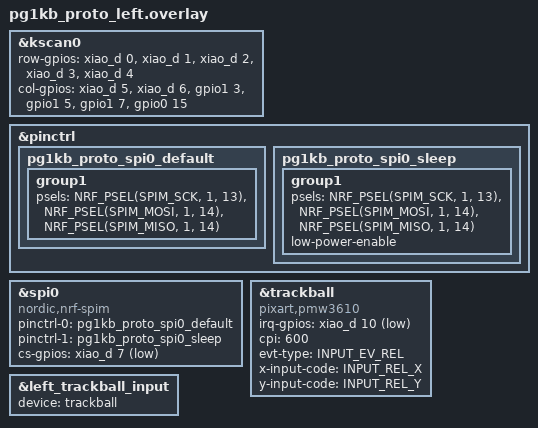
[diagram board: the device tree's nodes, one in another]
#include "pg1kb_proto.dtsi"

#include <zephyr/dt-bindings/input/input-event-codes.h>

&kscan0 {
    row-gpios
        = <&xiao_d 0 (GPIO_ACTIVE_HIGH | GPIO_PULL_DOWN)>
        , <&xiao_d 1 (GPIO_ACTIVE_HIGH | GPIO_PULL_DOWN)>
        , <&xiao_d 2 (GPIO_ACTIVE_HIGH | GPIO_PULL_DOWN)>
        , <&xiao_d 3 (GPIO_ACTIVE_HIGH | GPIO_PULL_DOWN)>
        , <&xiao_d 4 (GPIO_ACTIVE_HIGH | GPIO_PULL_DOWN)>
        ;

    col-gpios
        = <&xiao_d 5 GPIO_ACTIVE_HIGH>
        , <&xiao_d 6 GPIO_ACTIVE_HIGH>
        , <&gpio1 3 GPIO_ACTIVE_HIGH>
        , <&gpio1 5 GPIO_ACTIVE_HIGH>
        , <&gpio1 7 GPIO_ACTIVE_HIGH>
        , <&gpio0 15 GPIO_ACTIVE_HIGH>
        ;
};

&pinctrl {
    pg1kb_proto_spi0_default: pg1kb_proto_spi0_default {
        group1 {
            psels = <NRF_PSEL(SPIM_SCK, 1, 13)>,
                    <NRF_PSEL(SPIM_MOSI, 1, 14)>,
                    <NRF_PSEL(SPIM_MISO, 1, 14)>;
        };
    };

    pg1kb_proto_spi0_sleep: pg1kb_proto_spi0_sleep {
        group1 {
            psels = <NRF_PSEL(SPIM_SCK, 1, 13)>,
                    <NRF_PSEL(SPIM_MOSI, 1, 14)>,
                    <NRF_PSEL(SPIM_MISO, 1, 14)>;
            low-power-enable;
        };
    };
};

&spi0 {
    status = "okay";
    compatible = "nordic,nrf-spim";
    pinctrl-0 = <&pg1kb_proto_spi0_default>;
    pinctrl-1 = <&pg1kb_proto_spi0_sleep>;
    pinctrl-names = "default", "sleep";
    cs-gpios = <&xiao_d 7 GPIO_ACTIVE_LOW>;
};

&trackball {
    status = "okay";
    compatible = "pixart,pmw3610";
    irq-gpios = <&xiao_d 10 (GPIO_ACTIVE_LOW | GPIO_PULL_UP)>;
    cpi = <600>;
    evt-type = <INPUT_EV_REL>;
    x-input-code = <INPUT_REL_X>;
    y-input-code = <INPUT_REL_Y>;
};

&left_trackball_input {
    device = <&trackball>;
};
